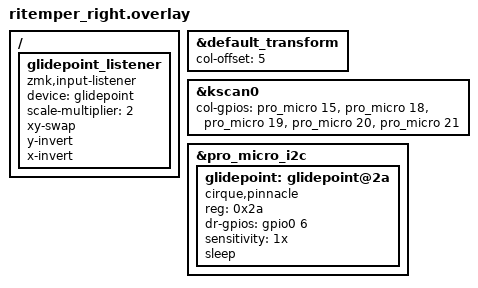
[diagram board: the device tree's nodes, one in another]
/*
 * Copyright (c) 2020 Pete Johanson
 *
 * SPDX-License-Identifier: MIT
 */

#include "ritemper.dtsi"
#include <input/processors.dtsi>

&default_transform {
    col-offset = <5>;
};

&kscan0 {
    col-gpios
        = <&pro_micro 15 GPIO_ACTIVE_HIGH>
        , <&pro_micro 18 GPIO_ACTIVE_HIGH>
        , <&pro_micro 19 GPIO_ACTIVE_HIGH>
        , <&pro_micro 20 GPIO_ACTIVE_HIGH>
        , <&pro_micro 21 GPIO_ACTIVE_HIGH>
        ;
};

&pro_micro_i2c {
    status = "okay";
    glidepoint: glidepoint@2a {
        compatible = "cirque,pinnacle";
        reg = <0x2a>;
        status = "okay";
        dr-gpios = <&gpio0 6 (GPIO_ACTIVE_HIGH)>;

        sensitivity = "1x";
        sleep;
        //no-taps;
    };
};

/ {
  glidepoint_listener {
    compatible = "zmk,input-listener";
    device = <&glidepoint>;
    scale-multiplier = <2>;
    xy-swap;
    y-invert;
    x-invert;
  };
};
